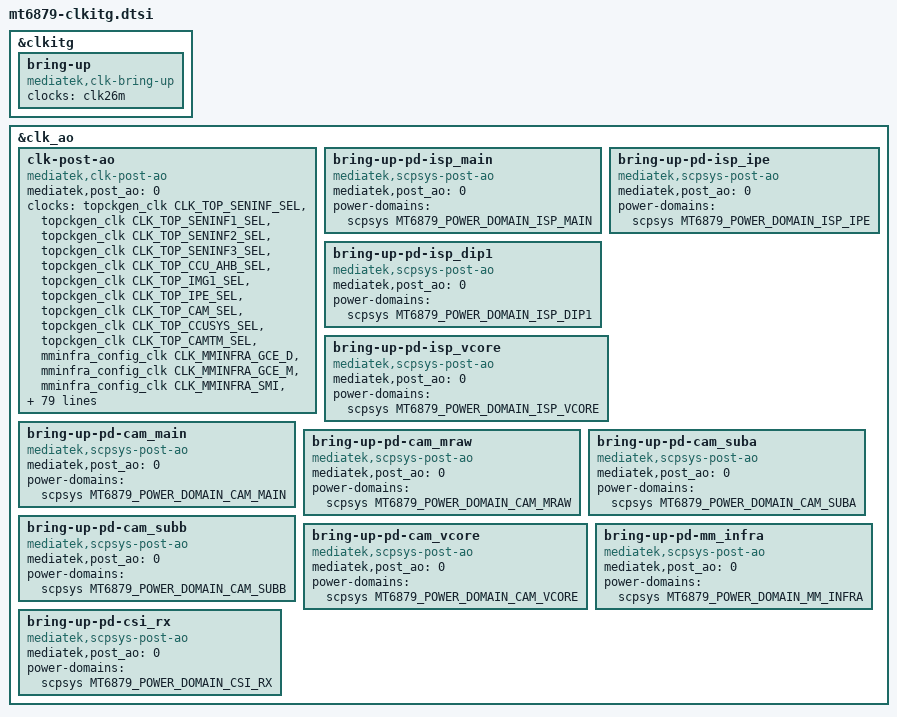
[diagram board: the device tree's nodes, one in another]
// SPDX-License-Identifier: (GPL-2.0 OR MIT)
/*
 * Copyright (C) 2021 MediaTek Inc.
 * Author: Owen Chen <owen.chen@mediatek.com>
 */

&clkitg {
	status = "okay";
	bring-up {
		compatible = "mediatek,clk-bring-up";
		clocks =
			<&clk26m>;
	};
};

&clk_ao {
	status = "okay";
	clk-post-ao {
		compatible = "mediatek,clk-post-ao";
		/*
		 * 1: post clk-ao,
		 * 0: no clk-ao,
		 */
		mediatek,post_ao = <0>;
		clocks = <&topckgen_clk CLK_TOP_SENINF_SEL>,
			<&topckgen_clk CLK_TOP_SENINF1_SEL>,
			<&topckgen_clk CLK_TOP_SENINF2_SEL>,
			<&topckgen_clk CLK_TOP_SENINF3_SEL>,
			<&topckgen_clk CLK_TOP_CCU_AHB_SEL>,
			<&topckgen_clk CLK_TOP_IMG1_SEL>,
			<&topckgen_clk CLK_TOP_IPE_SEL>,
			<&topckgen_clk CLK_TOP_CAM_SEL>,
			<&topckgen_clk CLK_TOP_CCUSYS_SEL>,
			<&topckgen_clk CLK_TOP_CAMTM_SEL>,
			<&mminfra_config_clk CLK_MMINFRA_GCE_D>,
			<&mminfra_config_clk CLK_MMINFRA_GCE_M>,
			<&mminfra_config_clk CLK_MMINFRA_SMI>,
			<&mminfra_config_clk CLK_MMINFRA_GCE_26M>,
			<&imgsys_main_clk CLK_IMG_LARB9>,
			<&imgsys_main_clk CLK_IMG_TRAW0>,
			<&imgsys_main_clk CLK_IMG_TRAW1>,
			<&imgsys_main_clk CLK_IMG_VCORE_GALS>,
			<&imgsys_main_clk CLK_IMG_DIP0>,
			<&imgsys_main_clk CLK_IMG_WPE0>,
			<&imgsys_main_clk CLK_IMG_IPE>,
			<&imgsys_main_clk CLK_IMG_WPE1>,
			<&imgsys_main_clk CLK_IMG_WPE2>,
			<&imgsys_main_clk CLK_IMG_GALS>,
			<&ipesys_clk CLK_IPE_DPE>,
			<&ipesys_clk CLK_IPE_FDVT>,
			<&ipesys_clk CLK_IPE_ME>,
			<&ipesys_clk CLK_IPESYS_TOP>,
			<&ipesys_clk CLK_IPE_SMI_LARB12>,
			<&dip_top_dip1_clk CLK_DIP_TOP_DIP1_DIP_TOP>,
			<&dip_top_dip1_clk CLK_DIP_TOP_DIP1_LARB10>,
			<&dip_nr_dip1_clk CLK_DIP_NR_DIP1_DIP_NR>,
			<&dip_nr_dip1_clk CLK_DIP_NR_DIP1_LARB15>,
			<&wpe1_dip1_clk CLK_WPE1_DIP1_WPE>,
			<&wpe1_dip1_clk CLK_WPE1_DIP1_LARB11>,
			<&wpe2_dip1_clk CLK_WPE2_DIP1_WPE>,
			<&wpe2_dip1_clk CLK_WPE2_DIP1_LARB11>,
			<&wpe3_dip1_clk CLK_WPE3_DIP1_WPE>,
			<&wpe3_dip1_clk CLK_WPE3_DIP1_LARB11>,
			<&cam_main_r1a_clk CLK_CAM_MAIN_LARB13_CON>,
			<&cam_main_r1a_clk CLK_CAM_MAIN_LARB14_CON>,
			<&cam_main_r1a_clk CLK_CAM_MAIN_CAM_CON>,
			<&cam_main_r1a_clk CLK_CAM_MAIN_CAM_SUBA_CON>,
			<&cam_main_r1a_clk CLK_CAM_MAIN_CAM_SUBB_CON>,
			<&cam_main_r1a_clk CLK_CAM_MAIN_CAM_SUBC_CON>,
			<&cam_main_r1a_clk CLK_CAM_MAIN_CAM_MRAW_CON>,
			<&cam_main_r1a_clk CLK_CAM_MAIN_CAMTG_CON>,
			<&cam_main_r1a_clk CLK_CAM_MAIN_SENINF_CON>,
			<&cam_main_r1a_clk CLK_CAM_MAIN_GCAMSVA_CON>,
			<&cam_main_r1a_clk CLK_CAM_MAIN_GCAMSVB_CON>,
			<&cam_main_r1a_clk CLK_CAM_MAIN_GCAMSVC_CON>,
			<&cam_main_r1a_clk CLK_CAM_MAIN_GCAMSVD_CON>,
			<&cam_main_r1a_clk CLK_CAM_MAIN_GCAMSVE_CON>,
			<&cam_main_r1a_clk CLK_CAM_MAIN_GCAMSVF_CON>,
			<&cam_main_r1a_clk CLK_CAM_MAIN_GCAMSVG_CON>,
			<&cam_main_r1a_clk CLK_CAM_MAIN_GCAMSVH_CON>,
			<&cam_main_r1a_clk CLK_CAM_MAIN_GCAMSVI_CON>,
			<&cam_main_r1a_clk CLK_CAM_MAIN_GCAMSVJ_CON>,
			<&cam_main_r1a_clk CLK_CAM_MAIN_CAMSV_TOP_CON>,
			<&cam_main_r1a_clk CLK_CAM_MAIN_CAMSV_CQ_A_CON>,
			<&cam_main_r1a_clk CLK_CAM_MAIN_CAMSV_CQ_B_CON>,
			<&cam_main_r1a_clk CLK_CAM_MAIN_CAMSV_CQ_C_CON>,
			<&cam_main_r1a_clk CLK_CAM_MAIN_ADL_CON>,
			<&cam_main_r1a_clk CLK_CAM_MAIN_ASG_CON>,
			<&cam_main_r1a_clk CLK_CAM_MAIN_PDA0_CON>,
			<&cam_main_r1a_clk CLK_CAM_MAIN_PDA1_CON>,
			<&cam_main_r1a_clk CLK_CAM_MAIN_PDA2_CON>,
			<&cam_main_r1a_clk CLK_CAM_MAIN_FAKE_ENG_CON>,
			<&camsys_rawa_clk CLK_CAM_RA_LARBX>,
			<&camsys_rawa_clk CLK_CAM_RA_CAM>,
			<&camsys_rawa_clk CLK_CAM_RA_CAMTG>,
			<&camsys_yuva_clk CLK_CAM_YA_LARBX>,
			<&camsys_yuva_clk CLK_CAM_YA_CAM>,
			<&camsys_yuva_clk CLK_CAM_YA_CAMTG>,
			<&camsys_rawb_clk CLK_CAM_RB_LARBX>,
			<&camsys_rawb_clk CLK_CAM_RB_CAM>,
			<&camsys_rawb_clk CLK_CAM_RB_CAMTG>,
			<&camsys_yuvb_clk CLK_CAM_YB_LARBX>,
			<&camsys_yuvb_clk CLK_CAM_YB_CAM>,
			<&camsys_yuvb_clk CLK_CAM_YB_CAMTG>,
			<&camsys_mraw_clk CLK_CAM_MR_LARBX>,
			<&camsys_mraw_clk CLK_CAM_MR_CAMTG>,
			<&camsys_mraw_clk CLK_CAM_MR_MRAW0>,
			<&camsys_mraw_clk CLK_CAM_MR_MRAW1>,
			<&camsys_mraw_clk CLK_CAM_MR_MRAW2>,
			<&camsys_mraw_clk CLK_CAM_MR_MRAW3>,
			<&camsys_mraw_clk CLK_CAM_MR_PDA0>,
			<&camsys_mraw_clk CLK_CAM_MR_PDA1>,
			<&ccu_main_clk CLK_CCU_LARB19>,
			<&ccu_main_clk CLK_CCU_AHB>,
			<&ccu_main_clk CLK_CCUSYS_CCU0>,
			<&ccu_main_clk CLK_CCUSYS_CCU1>;
	};

	bring-up-pd-isp_main {
		compatible = "mediatek,scpsys-post-ao";
		/*
		 * 1: post clk-ao,
		 * 0: no clk-ao,
		 */
		mediatek,post_ao = <0>;
		power-domains = <&scpsys MT6879_POWER_DOMAIN_ISP_MAIN>;
	};

	bring-up-pd-isp_dip1 {
		compatible = "mediatek,scpsys-post-ao";
		/*
		 * 1: post clk-ao,
		 * 0: no clk-ao,
		 */
		mediatek,post_ao = <0>;
		power-domains = <&scpsys MT6879_POWER_DOMAIN_ISP_DIP1>;
	};

	bring-up-pd-isp_ipe {
		compatible = "mediatek,scpsys-post-ao";
		/*
		 * 1: post clk-ao,
		 * 0: no clk-ao,
		 */
		mediatek,post_ao = <0>;
		power-domains = <&scpsys MT6879_POWER_DOMAIN_ISP_IPE>;
	};

	bring-up-pd-isp_vcore {
		compatible = "mediatek,scpsys-post-ao";
		/*
		 * 1: post clk-ao,
		 * 0: no clk-ao,
		 */
		mediatek,post_ao = <0>;
		power-domains = <&scpsys MT6879_POWER_DOMAIN_ISP_VCORE>;
	};

	bring-up-pd-cam_main {
		compatible = "mediatek,scpsys-post-ao";
		/*
		 * 1: post clk-ao,
		 * 0: no clk-ao,
		 */
		mediatek,post_ao = <0>;
		power-domains = <&scpsys MT6879_POWER_DOMAIN_CAM_MAIN>;
	};

	bring-up-pd-cam_mraw {
		compatible = "mediatek,scpsys-post-ao";
		/*
		 * 1: post clk-ao,
		 * 0: no clk-ao,
		 */
		mediatek,post_ao = <0>;
		power-domains = <&scpsys MT6879_POWER_DOMAIN_CAM_MRAW>;
	};

	bring-up-pd-cam_suba {
		compatible = "mediatek,scpsys-post-ao";
		/*
		 * 1: post clk-ao,
		 * 0: no clk-ao,
		 */
		mediatek,post_ao = <0>;
		power-domains = <&scpsys MT6879_POWER_DOMAIN_CAM_SUBA>;
	};

	bring-up-pd-cam_subb {
		compatible = "mediatek,scpsys-post-ao";
		/*
		 * 1: post clk-ao,
		 * 0: no clk-ao,
		 */
		mediatek,post_ao = <0>;
		power-domains = <&scpsys MT6879_POWER_DOMAIN_CAM_SUBB>;
	};

	bring-up-pd-cam_vcore {
		compatible = "mediatek,scpsys-post-ao";
		/*
		 * 1: post clk-ao,
		 * 0: no clk-ao,
		 */
		mediatek,post_ao = <0>;
		power-domains = <&scpsys MT6879_POWER_DOMAIN_CAM_VCORE>;
	};

	bring-up-pd-mm_infra {
		compatible = "mediatek,scpsys-post-ao";
		/*
		 * 1: post clk-ao,
		 * 0: no clk-ao,
		 */
		mediatek,post_ao = <0>;
		power-domains = <&scpsys MT6879_POWER_DOMAIN_MM_INFRA>;
	};

	bring-up-pd-csi_rx {
		compatible = "mediatek,scpsys-post-ao";
		/*
		 * 1: post clk-ao,
		 * 0: no clk-ao,
		 */
		mediatek,post_ao = <0>;
		power-domains = <&scpsys MT6879_POWER_DOMAIN_CSI_RX>;
	};
};

